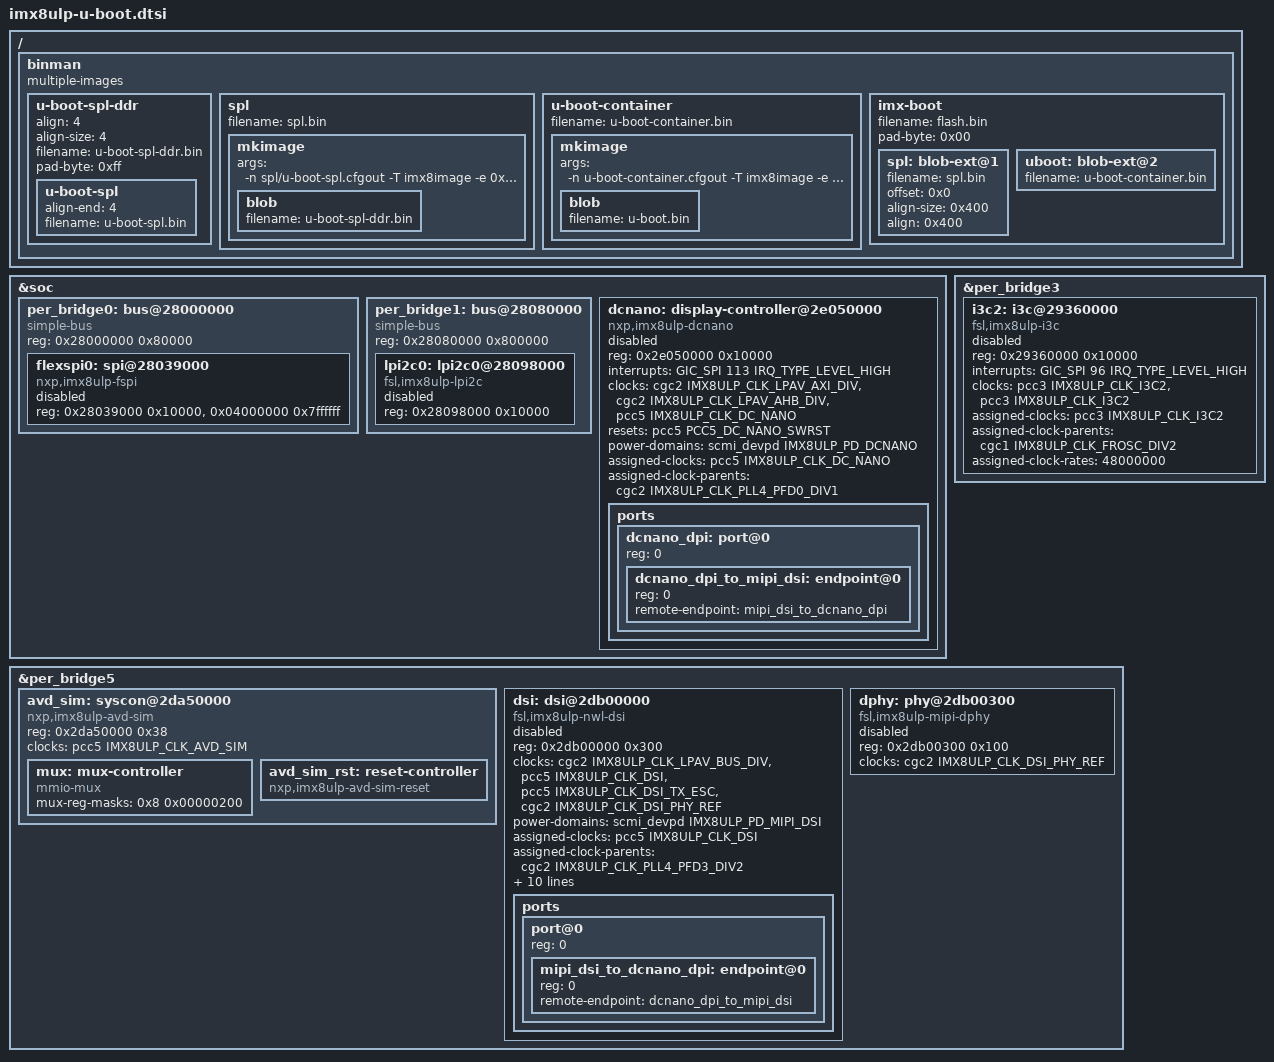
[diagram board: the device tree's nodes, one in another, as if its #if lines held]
// SPDX-License-Identifier: GPL-2.0+

#include <dt-bindings/reset/imx8ulp-pcc-reset.h>
#include <dt-bindings/reset/imx8ulp-sim-reset.h>

#ifdef CONFIG_BINMAN
/ {
	binman: binman {
		multiple-images;
	};
};

&binman {
	u-boot-spl-ddr {
		align = <4>;
		align-size = <4>;
		filename = "u-boot-spl-ddr.bin";
		pad-byte = <0xff>;

		u-boot-spl {
			align-end = <4>;
			filename = "u-boot-spl.bin";
		};
	};

	spl {
		filename = "spl.bin";

		mkimage {
			args = "-n spl/u-boot-spl.cfgout -T imx8image -e 0x22020000";

			blob {
				filename = "u-boot-spl-ddr.bin";
			};
		};
	};

	u-boot-container {
		filename = "u-boot-container.bin";

		mkimage {
			args = "-n u-boot-container.cfgout -T imx8image -e 0x0";

			blob {
				filename = "u-boot.bin";
			};
		};
	};

	imx-boot {
		filename = "flash.bin";
		pad-byte = <0x00>;

		spl: blob-ext@1 {
			filename = "spl.bin";
			offset = <0x0>;
			align-size = <0x400>;
			align = <0x400>;
		};

		uboot: blob-ext@2 {
			filename = "u-boot-container.bin";
		};
	};
};
#endif

&soc {
	per_bridge0: bus@28000000 {
		compatible = "simple-bus";
		reg = <0x28000000 0x80000>;
		#address-cells = <1>;
		#size-cells = <1>;
		ranges;

		flexspi0: spi@28039000 {
			#address-cells = <1>;
			#size-cells = <0>;
			compatible = "nxp,imx8ulp-fspi";
			reg = <0x28039000 0x10000>,
				<0x04000000 0x7ffffff>;
			reg-names = "fspi_base", "fspi_mmap";
			status = "disabled";
		};
	};

	per_bridge1: bus@28080000 {
		compatible = "simple-bus";
		reg = <0x28080000 0x800000>;
		#address-cells = <1>;
		#size-cells = <1>;
		ranges;

		lpi2c0: lpi2c0@28098000 {
			compatible = "fsl,imx8ulp-lpi2c", "fsl,imx7ulp-lpi2c";
			reg = <0x28098000 0x10000>;
			status = "disabled";
		};
	};

	dcnano: display-controller@2e050000 {
		compatible = "nxp,imx8ulp-dcnano";
		reg = <0x2e050000 0x10000>;
		interrupts = <GIC_SPI 113 IRQ_TYPE_LEVEL_HIGH>;
		clocks = <&cgc2 IMX8ULP_CLK_LPAV_AXI_DIV>,
			 <&cgc2 IMX8ULP_CLK_LPAV_AHB_DIV>,
			 <&pcc5 IMX8ULP_CLK_DC_NANO>;
		clock-names = "axi", "ahb", "pixel";
		resets = <&pcc5 PCC5_DC_NANO_SWRST>;
		power-domains = <&scmi_devpd IMX8ULP_PD_DCNANO>;
		assigned-clocks = <&pcc5 IMX8ULP_CLK_DC_NANO>;
		assigned-clock-parents = <&cgc2 IMX8ULP_CLK_PLL4_PFD0_DIV1>;
		status = "disabled";

		ports {
			#address-cells = <1>;
			#size-cells = <0>;

			dcnano_dpi: port@0 {
				#address-cells = <1>;
				#size-cells = <0>;
				reg = <0>;

				dcnano_dpi_to_mipi_dsi: endpoint@0 {
					reg = <0>;
					remote-endpoint = <&mipi_dsi_to_dcnano_dpi>;
				};
			};
		};
	};
};

&per_bridge3 {
	i3c2: i3c@29360000 {
		compatible = "fsl,imx8ulp-i3c";
		reg = <0x29360000 0x10000>;
		#address-cells = <1>;
		#size-cells = <0>;
		interrupts = <GIC_SPI 96 IRQ_TYPE_LEVEL_HIGH>;
		clocks = <&pcc3 IMX8ULP_CLK_I3C2>,
			 <&pcc3 IMX8ULP_CLK_I3C2>;
		clock-names = "per", "ipg";
		assigned-clocks = <&pcc3 IMX8ULP_CLK_I3C2>;
		assigned-clock-parents = <&cgc1 IMX8ULP_CLK_FROSC_DIV2>;
		assigned-clock-rates = <48000000>;
		status = "disabled";
	};
};

&per_bridge5 {
	avd_sim: syscon@2da50000 {
		compatible = "nxp,imx8ulp-avd-sim", "syscon", "simple-mfd";
		reg = <0x2da50000 0x38>;
		clocks = <&pcc5 IMX8ULP_CLK_AVD_SIM>;

		mux: mux-controller {
			compatible = "mmio-mux";
			#mux-control-cells = <1>;
			mux-reg-masks = <0x8 0x00000200>; /* DSI_DPI2_EPDC_DCNANO_MUX_SEL */
		};

		avd_sim_rst: reset-controller {
			compatible = "nxp,imx8ulp-avd-sim-reset";
			#reset-cells = <1>;
		};
	};

	dsi: dsi@2db00000 {
		compatible = "fsl,imx8ulp-nwl-dsi";
		reg = <0x2db00000 0x300>;
		#address-cells = <1>;
		#size-cells = <0>;
		clocks = <&cgc2 IMX8ULP_CLK_LPAV_BUS_DIV>,
			 <&pcc5 IMX8ULP_CLK_DSI>,
			 <&pcc5 IMX8ULP_CLK_DSI_TX_ESC>,
			 <&cgc2 IMX8ULP_CLK_DSI_PHY_REF>;
		clock-names = "core", "rx_esc", "tx_esc", "phy_ref";
		power-domains = <&scmi_devpd IMX8ULP_PD_MIPI_DSI>;
		assigned-clocks = <&pcc5 IMX8ULP_CLK_DSI>;
		assigned-clock-parents = <&cgc2 IMX8ULP_CLK_PLL4_PFD3_DIV2>;
		assigned-clock-rates = <79200000>;
		interrupts = <GIC_SPI 114 IRQ_TYPE_LEVEL_HIGH>;
		mux-controls = <&mux 0>;
		csr = <&avd_sim>;
		phys = <&dphy>;
		phy-names = "dphy";
		resets = <&avd_sim_rst IMX8ULP_SIM_RESET_MIPI_DSI_RST_BYTE_N>,
			 <&avd_sim_rst IMX8ULP_SIM_RESET_MIPI_DSI_RST_DPI_N>,
			 <&avd_sim_rst IMX8ULP_SIM_RESET_MIPI_DSI_RST_ESC_N>,
			 <&pcc5 PCC5_DSI_SWRST>;
		reset-names = "byte", "dpi", "esc", "pclk";
		status = "disabled";

		ports {
			#address-cells = <1>;
			#size-cells = <0>;

			port@0 {
				#address-cells = <1>;
				#size-cells = <0>;
				reg = <0>;

				mipi_dsi_to_dcnano_dpi: endpoint@0 {
					reg = <0>;
					remote-endpoint = <&dcnano_dpi_to_mipi_dsi>;
				};
			};
		};
	};

	dphy: phy@2db00300 {
		compatible = "fsl,imx8ulp-mipi-dphy";
		reg = <0x2db00300 0x100>;
		clocks = <&cgc2 IMX8ULP_CLK_DSI_PHY_REF>;
		clock-names = "phy_ref";
		#phy-cells = <0>;
		status = "disabled";
	};
};
